# CH583SFR register map
Vendor: WCH Ltd.; Series: CH58x; File version: 1.1
WCH wireless MCU CH58x Family Support, Drivers
CPU: RISC-V r0p0, little endian, no MPU, no FPU, 2 interrupt priority bits
Registers are 8-bit, read-write, reset 0x0 unless marked. A register's access mark holds for its fields unless they carry their own. Offsets are from the block's base; lines under a group give offsets from that group; [hi:lo] are bit positions; {n}, {i} and the like mark numbered series; 'fields as' and 'values as' point back to an identical list; <NAME> marks a mode.

## Memory map
0x40001000 SYS size 0x400 — System Control Register
0x40001000 ADC — System Control Register
0x40001000 GPIOA — System Control Register
0x40001000 GPIOB — System Control Register
0x40002000 TMR0 size 0x400 — Timer0 register
0x40002400 TMR1 size 0x400 — Timer1 register
0x40002800 TMR2 size 0x400 — Timer2 register
0x40002C00 TMR3 size 0x400 — Timer3 register
0x40003000 UART0 size 0x400
0x40003400 UART1 size 0x400
0x40003800 UART2 size 0x400
0x40003C00 UART3 size 0x400
0x40004000 SPI0 size 0x400
0x40004400 SPI1 size 0x400
0x40004800 I2C size 0x400
0x40005000 PWMx size 0x400
0x40008000 USB size 0x400
0x40008400 USB2 size 0x400
0xE000E000 PFIC size 0x1000 — Program Fast Interrupt Controller
0xE000F000 Systick size 0x100

## ADC — System Control Register
Base 0x40001000
0x58 CHANNEL reset 0xF — RW, ADC input channel selection
  [3:0] CH_INX — RW, ADC input channel index
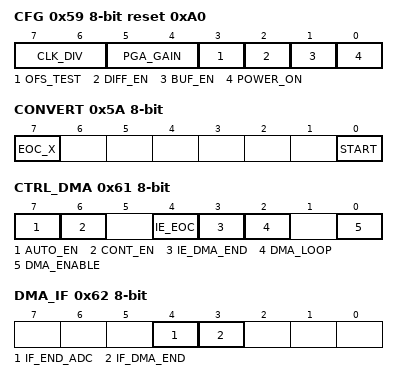
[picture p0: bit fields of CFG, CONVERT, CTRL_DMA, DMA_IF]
0x59 CFG reset 0xA0 — RW, ADC configure
  [7:6] CLK_DIV — RW, select ADC clock frequency: 00=3.2MHz, 01=2.67MHz, 10=5.33MHz, 11=4MHz
    0=10; 1=4; 2=6; 3=8
  [5:4] PGA_GAIN — RW, set ADC input PGA gain: 00=-12dB, 01=-6dB, 10=0dB, 11=6dB
    0=1_4; 1=1_2; 2=1; 3=2
  [3] OFS_TEST — RW, enable ADC offset test mode: 0=normal mode, 1=short to test offset
  [2] DIFF_EN — RW, ADC input channel mode: 0=single-end, 1=differnetial
  [1] BUF_EN — RW, ADC input buffer enable
  [0] POWER_ON — RW, ADC power control: 0=power down, 1=power on
0x5A CONVERT — RW, ADC convert control
  [7] EOC_X ro — RO, end of ADC conversion flag
  [0] START — RW, ADC convert start control: 0=stop ADC convert, 1=start an ADC convert, auto clear
0x5B TEM_SENSOR — RW, temperature sensor control
  [7] TEM_SEN_PWR_ON — RW, temperature sensor power control: 0=power down, 1=power on
0x5C DATA 16-bit ro — RO, ADC data
  [11:0] DATA — RO, ADC conversion data
0x5E INT_FLAG ro — RO, ADC interrupt flag register
  [7] IF_EOC — RO, ADC conversion interrupt flag: 0=free or converting, 1=end of conversion, interrupt action, write R8_ADC_CONVERT to clear flag
0x60 DMA_CTRL — RO, ADC DMA control and status register
  [7:0] DMA_CTRL — RW, ADC DMA enable
0x61 CTRL_DMA — RW, ADC DMA control
  [7] AUTO_EN — RW, enable auto continuing ADC for DMA
  [6] CONT_EN — RW, enable contineous conversion ADC
  [4] IE_EOC — RW, enable interrupt for end of ADC conversion
  [3] IE_DMA_END — RW, enable interrupt for ADC DMA completion
  [2] DMA_LOOP — RW, ADC DMA address loop enable
  [0] DMA_ENABLE — RW, ADC DMA enable
0x62 DMA_IF — RO, ADC interrupt flag
  [4] IF_END_ADC — interrupt flag for end of ADC conversion
  [3] IF_DMA_END — interrupt flag for ADC DMA completion
0x63 AUTO_CYCLE — RO, ADC interrupt flag
  [7:0] AUTO_CYCLE — auto ADC cycle value, unit is 16 Fsys
0x64 DMA_NOW ro — RO, ADC DMA current address
  [7:0] DMA_NOW — ADC DMA current address
0x68 DMA_BEG 16-bit — RW, ADC DMA begin address
  [15:0] DMA_BEG — ADC DMA begin address
0x6C DMA_END 16-bit — RW, ADC DMA end address
  [15:0] DMA_END — ADC DMA end address

## GPIOA — System Control Register
Base 0x40001000
0x90 INT_EN 16-bit — RW, GPIO PA interrupt enable
  [15:0] INT_EN — GPIO PA interrupt enable
0x94 INT_MODE 16-bit — RW, GPIO PA interrupt mode: 0=level action, 1=edge action
  [15:0] INT_MODE — GPIO PA interrupt mode
0x9C INT_IF 16-bit — RW1, GPIO PA interrupt flag
  [15:0] INT_IF — GPIO PA interrupt flag
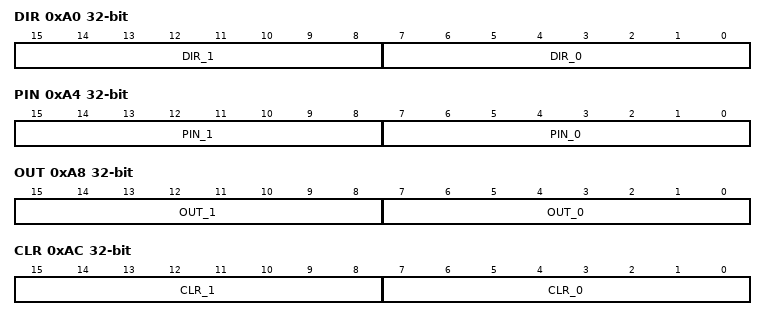
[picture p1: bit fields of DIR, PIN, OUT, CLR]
0xA0 DIR 32-bit — RW, GPIO PA I/O direction: 0=in, 1=out
  [15:8] DIR_1 — GPIO PA I/O direction byte 1
  [7:0] DIR_0 — GPIO PA I/O direction byte 0
0xA4 PIN 32-bit ro — RO, GPIO PA input
  [15:8] PIN_1 — GPIO PA input byte 1
  [7:0] PIN_0 — GPIO PA input byte 0
0xA8 OUT 32-bit — RW, GPIO PA output
  [15:8] OUT_1 — GPIO PA output byte 1
  [7:0] OUT_0 — GPIO PA output byte 0
0xAC CLR 32-bit — WZ, GPIO PA clear output: 0=keep, 1=clear
  [15:8] CLR_1 — GPIO PA clear output byte 1
  [7:0] CLR_0 — GPIO PA clear output byte 0
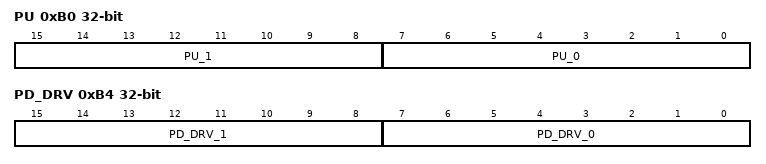
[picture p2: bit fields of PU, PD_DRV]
0xB0 PU 32-bit — RW, GPIO PA pullup resistance enable
  [15:8] PU_1 — GPIO PA pullup resistance enable byte 0
  [7:0] PU_0 — GPIO PA pullup resistance enable byte 0
0xB4 PD_DRV 32-bit — RW, PA pulldown for input or PA driving capability for output
  [15:8] PD_DRV_1 — PA pulldown for input or PA driving capability for output byte 1
  [7:0] PD_DRV_0 — PA pulldown for input or PA driving capability for output byte 0
